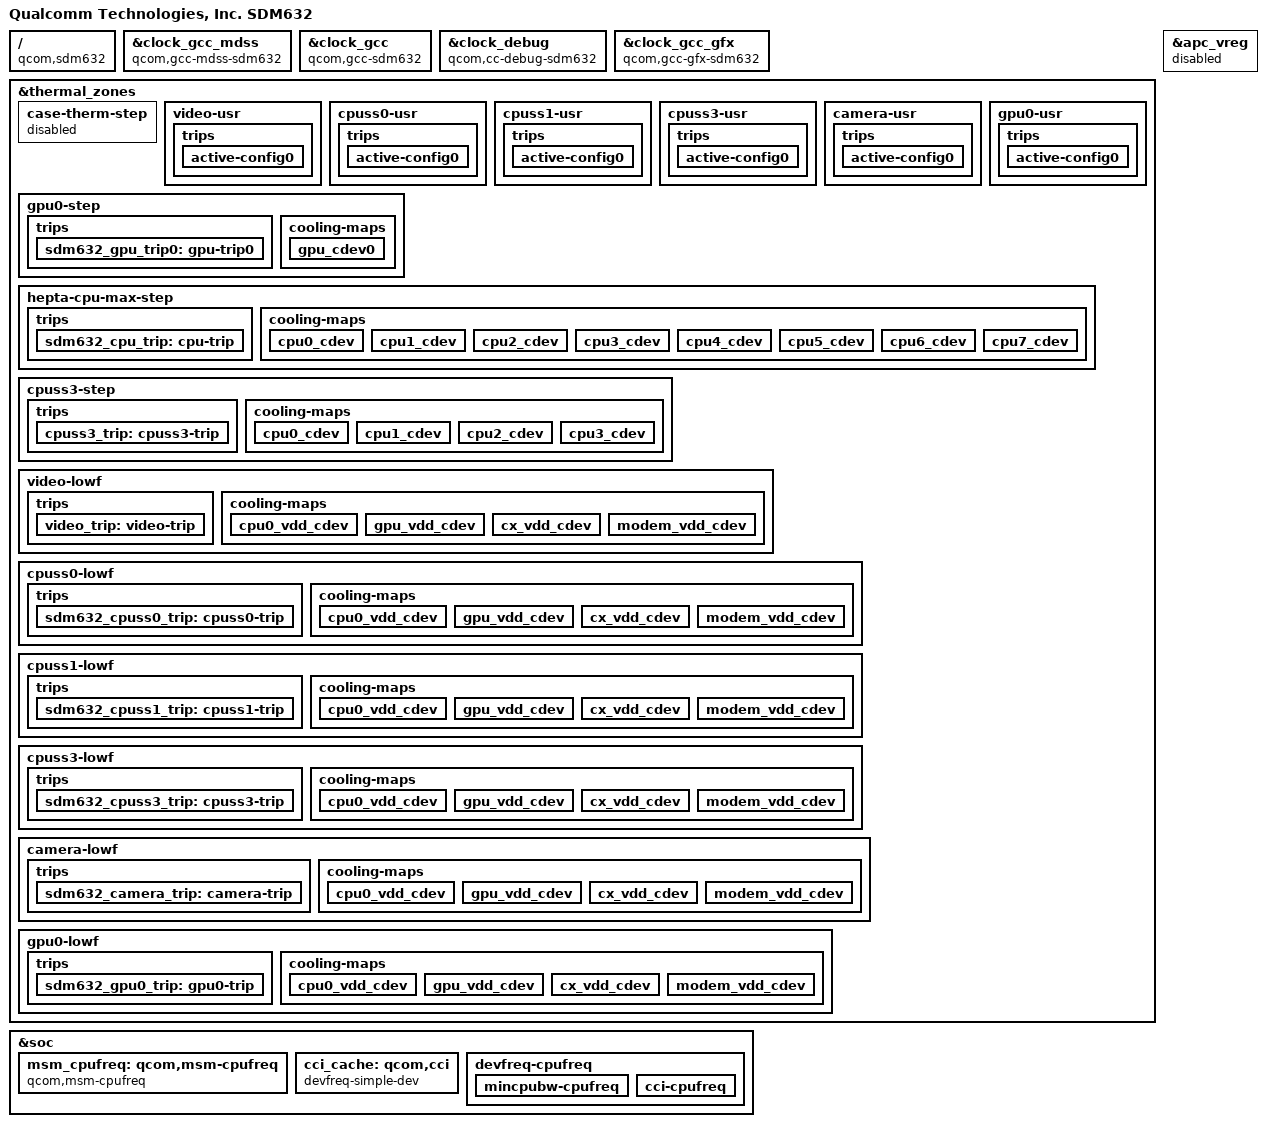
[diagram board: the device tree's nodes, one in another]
/*
 * Copyright (c) 2018, The Linux Foundation. All rights reserved.
 *
 * This program is free software; you can redistribute it and/or modify
 * it under the terms of the GNU General Public License version 2 and
 * only version 2 as published by the Free Software Foundation.
 *
 * This program is distributed in the hope that it will be useful,
 * but WITHOUT ANY WARRANTY; without even the implied warranty of
 * MERCHANTABILITY or FITNESS FOR A PARTICULAR PURPOSE.  See the
 * GNU General Public License for more details.
 */

#include "msm8953.dtsi"
#include "sdm632-cpu.dtsi"

/ {
	model = "Qualcomm Technologies, Inc. SDM632";
	compatible = "qcom,sdm632";
	qcom,msm-id = <349 0x0>;
	qcom,msm-name = "SDM632";
};

&clock_gcc_mdss {
	compatible = "qcom,gcc-mdss-sdm632";
};

&clock_gcc {
	compatible = "qcom,gcc-sdm632";
};

&clock_debug {
	compatible = "qcom,cc-debug-sdm632";
};

&clock_gcc_gfx {
	compatible = "qcom,gcc-gfx-sdm632";
};

&thermal_zones {
	/delete-node/ camera-usr;
	/delete-node/ apc1-l2-usr;
	/delete-node/ apc0-cpu0-usr;
	/delete-node/ apc0-cpu1-usr;
	/delete-node/ apc0-cpu2-usr;
	/delete-node/ apc0-cpu3-usr;
	/delete-node/ apc0-l2-usr;
	/delete-node/ gpu0-usr;
	/delete-node/ gpu1-usr;
	/delete-node/ gpu1-step;
	/delete-node/ deca-cpu-max-step;
	/delete-node/ apc0-cpu0-step;
	/delete-node/ apc0-cpu1-step;
	/delete-node/ apc0-cpu2-step;
	/delete-node/ apc0-cpu3-step;
	/delete-node/ camera-lowf;
	/delete-node/ apc1-l2-lowf;
	/delete-node/ apc0-cpu0-lowf;
	/delete-node/ apc0-cpu1-lowf;
	/delete-node/ apc0-cpu2-lowf;
	/delete-node/ apc0-cpu3-lowf;
	/delete-node/ apc0-l2-lowf;
	/delete-node/ gpu0-lowf;
	/delete-node/ gpu1-lowf;

	case-therm-step {
		status = "disabled";
	};

	video-usr {
		polling-delay-passive = <0>;
		polling-delay = <0>;
		thermal-governor = "user_space";
		thermal-sensors = <&tsens0 3>;
		trips {
			active-config0 {
				temperature = <125000>;
				hysteresis = <1000>;
				type = "passive";
			};
		};
	};

	cpuss0-usr {
		polling-delay-passive = <0>;
		polling-delay = <0>;
		thermal-sensors = <&tsens0 8>;
		thermal-governor = "user_space";
		trips {
			active-config0 {
				temperature = <125000>;
				hysteresis = <1000>;
				type = "passive";
			};
		};
	};

	cpuss1-usr {
		polling-delay-passive = <0>;
		polling-delay = <0>;
		thermal-sensors = <&tsens0 9>;
		thermal-governor = "user_space";
		trips {
			active-config0 {
				temperature = <125000>;
				hysteresis = <1000>;
				type = "passive";
			};
		};
	};

	cpuss3-usr {
		polling-delay-passive = <0>;
		polling-delay = <0>;
		thermal-sensors = <&tsens0 13>;
		thermal-governor = "user_space";
		trips {
			active-config0 {
				temperature = <125000>;
				hysteresis = <1000>;
				type = "passive";
			};
		};
	};

	camera-usr {
		polling-delay-passive = <0>;
		polling-delay = <0>;
		thermal-sensors = <&tsens0 14>;
		thermal-governor = "user_space";
		trips {
			active-config0 {
				temperature = <125000>;
				hysteresis = <1000>;
				type = "passive";
			};
		};
	};

	gpu0-usr {
		polling-delay-passive = <0>;
		polling-delay = <0>;
		thermal-sensors = <&tsens0 15>;
		thermal-governor = "user_space";
		trips {
			active-config0 {
				temperature = <125000>;
				hysteresis = <1000>;
				type = "passive";
			};
		};
	};

	gpu0-step {
		polling-delay-passive = <250>;
		polling-delay = <0>;
		thermal-sensors = <&tsens0 15>;
		thermal-governor = "step_wise";

		trips {
			sdm632_gpu_trip0: gpu-trip0 {
				temperature = <95000>;
				hysteresis = <0>;
				type = "passive";
			};
		};
		cooling-maps {
			gpu_cdev0 {
				trip = <&sdm632_gpu_trip0>;
				cooling-device =
					<&msm_gpu THERMAL_NO_LIMIT
						THERMAL_NO_LIMIT>;
			};
		};
	};

	hepta-cpu-max-step {
		polling-delay-passive = <50>;
		polling-delay = <100>;
		thermal-governor = "step_wise";

		trips {
			sdm632_cpu_trip:cpu-trip {
				temperature = <95000>;
				hysteresis = <0>;
				type = "passive";
			};
		};

		cooling-maps {
			cpu0_cdev {
				trip = <&sdm632_cpu_trip>;
				cooling-device =
					<&CPU0 THERMAL_NO_LIMIT
						(THERMAL_MAX_LIMIT-1)>;
			};
			cpu1_cdev {
				trip = <&sdm632_cpu_trip>;
				cooling-device =
					<&CPU1 THERMAL_NO_LIMIT
						(THERMAL_MAX_LIMIT-1)>;
			};
			cpu2_cdev {
				trip = <&sdm632_cpu_trip>;
				cooling-device =
					<&CPU2 THERMAL_NO_LIMIT
						(THERMAL_MAX_LIMIT-1)>;
			};
			cpu3_cdev {
				trip = <&sdm632_cpu_trip>;
				cooling-device =
					<&CPU3 THERMAL_NO_LIMIT
						(THERMAL_MAX_LIMIT-1)>;
			};
			cpu4_cdev {
				trip = <&sdm632_cpu_trip>;
				cooling-device =
					<&CPU4 THERMAL_NO_LIMIT
						(THERMAL_MAX_LIMIT-1)>;
			};
			cpu5_cdev {
				trip = <&sdm632_cpu_trip>;
				cooling-device =
					<&CPU5 THERMAL_NO_LIMIT
						(THERMAL_MAX_LIMIT-1)>;
			};
			cpu6_cdev {
				trip = <&sdm632_cpu_trip>;
				cooling-device =
					<&CPU6 THERMAL_NO_LIMIT
						(THERMAL_MAX_LIMIT-1)>;
			};
			cpu7_cdev {
				trip = <&sdm632_cpu_trip>;
				cooling-device =
					<&CPU7 THERMAL_NO_LIMIT
						(THERMAL_MAX_LIMIT-1)>;
			};
		};
	};

	cpuss3-step {
		polling-delay-passive = <0>;
		polling-delay = <0>;
		thermal-sensors = <&tsens0 13>;
		thermal-governor = "step_wise";

		trips {
			cpuss3_trip: cpuss3-trip {
				temperature = <105000>;
				hysteresis = <15000>;
				type = "passive";
			};
		};
		cooling-maps {
			cpu0_cdev {
				trip = <&cpuss3_trip>;
				cooling-device =
					<&CPU0 THERMAL_MAX_LIMIT
						THERMAL_MAX_LIMIT>;
			};
			cpu1_cdev {
				trip = <&cpuss3_trip>;
				cooling-device =
					<&CPU1 THERMAL_MAX_LIMIT
						THERMAL_MAX_LIMIT>;
			};
			cpu2_cdev {
				trip = <&cpuss3_trip>;
				cooling-device =
					<&CPU2 THERMAL_MAX_LIMIT
						THERMAL_MAX_LIMIT>;
			};
			cpu3_cdev {
				trip = <&cpuss3_trip>;
				cooling-device =
					<&CPU3 THERMAL_MAX_LIMIT
						THERMAL_MAX_LIMIT>;
			};
		};
	};

	video-lowf {
		polling-delay-passive = <0>;
		polling-delay = <0>;
		thermal-governor = "low_limits_floor";
		thermal-sensors = <&tsens0 3>;
		tracks-low;

		trips {
			video_trip: video-trip {
				temperature = <5000>;
				hysteresis = <5000>;
				type = "passive";
			};
		};
		cooling-maps {
			cpu0_vdd_cdev {
				trip = <&video_trip>;
				cooling-device = <&CPU0 (THERMAL_MAX_LIMIT - 4)
						(THERMAL_MAX_LIMIT - 4)>;
			};
			gpu_vdd_cdev {
				trip = <&video_trip>;
				cooling-device = <&msm_gpu 2 2>;
			};
			cx_vdd_cdev {
				trip = <&video_trip>;
				cooling-device = <&cx_cdev 0 0>;
			};
			modem_vdd_cdev {
				trip = <&video_trip>;
				cooling-device = <&modem_vdd 0 0>;
			};
		};
	};

	cpuss0-lowf {
		polling-delay-passive = <0>;
		polling-delay = <0>;
		thermal-governor = "low_limits_floor";
		thermal-sensors = <&tsens0 8>;
		tracks-low;

		trips {
			sdm632_cpuss0_trip: cpuss0-trip {
				temperature = <5000>;
				hysteresis = <5000>;
				type = "passive";
			};
		};
		cooling-maps {
			cpu0_vdd_cdev {
				trip = <&sdm632_cpuss0_trip>;
				cooling-device = <&CPU0 (THERMAL_MAX_LIMIT - 4)
						(THERMAL_MAX_LIMIT - 4)>;
			};
			gpu_vdd_cdev {
				trip = <&sdm632_cpuss0_trip>;
				cooling-device = <&msm_gpu 2 2>;
			};
			cx_vdd_cdev {
				trip = <&sdm632_cpuss0_trip>;
				cooling-device = <&cx_cdev 0 0>;
			};
			modem_vdd_cdev {
				trip = <&sdm632_cpuss0_trip>;
				cooling-device = <&modem_vdd 0 0>;
			};
		};
	};

	cpuss1-lowf {
		polling-delay-passive = <0>;
		polling-delay = <0>;
		thermal-governor = "low_limits_floor";
		thermal-sensors = <&tsens0 9>;
		tracks-low;

		trips {
			sdm632_cpuss1_trip: cpuss1-trip {
				temperature = <5000>;
				hysteresis = <5000>;
				type = "passive";
			};
		};
		cooling-maps {
			cpu0_vdd_cdev {
				trip = <&sdm632_cpuss1_trip>;
				cooling-device = <&CPU0 (THERMAL_MAX_LIMIT - 4)
						(THERMAL_MAX_LIMIT - 4)>;
			};
			gpu_vdd_cdev {
				trip = <&sdm632_cpuss1_trip>;
				cooling-device = <&msm_gpu 2 2>;
			};
			cx_vdd_cdev {
				trip = <&sdm632_cpuss1_trip>;
				cooling-device = <&cx_cdev 0 0>;
			};
			modem_vdd_cdev {
				trip = <&sdm632_cpuss1_trip>;
				cooling-device = <&modem_vdd 0 0>;
			};
		};
	};

	cpuss3-lowf {
		polling-delay-passive = <0>;
		polling-delay = <0>;
		thermal-governor = "low_limits_floor";
		thermal-sensors = <&tsens0 13>;
		tracks-low;

		trips {
			sdm632_cpuss3_trip: cpuss3-trip {
				temperature = <5000>;
				hysteresis = <5000>;
				type = "passive";
			};
		};
		cooling-maps {
			cpu0_vdd_cdev {
				trip = <&sdm632_cpuss3_trip>;
				cooling-device = <&CPU0 (THERMAL_MAX_LIMIT - 4)
						(THERMAL_MAX_LIMIT - 4)>;
			};
			gpu_vdd_cdev {
				trip = <&sdm632_cpuss3_trip>;
				cooling-device = <&msm_gpu 2 2>;
			};
			cx_vdd_cdev {
				trip = <&sdm632_cpuss3_trip>;
				cooling-device = <&cx_cdev 0 0>;
			};
			modem_vdd_cdev {
				trip = <&sdm632_cpuss3_trip>;
				cooling-device = <&modem_vdd 0 0>;
			};
		};
	};

	camera-lowf {
		polling-delay-passive = <0>;
		polling-delay = <0>;
		thermal-governor = "low_limits_floor";
		thermal-sensors = <&tsens0 14>;
		tracks-low;

		trips {
			sdm632_camera_trip: camera-trip {
				temperature = <5000>;
				hysteresis = <5000>;
				type = "passive";
			};
		};
		cooling-maps {
			cpu0_vdd_cdev {
				trip = <&sdm632_camera_trip>;
				cooling-device = <&CPU0 (THERMAL_MAX_LIMIT - 4)
						(THERMAL_MAX_LIMIT - 4)>;
			};
			gpu_vdd_cdev {
				trip = <&sdm632_camera_trip>;
				cooling-device = <&msm_gpu 2 2>;
			};
			cx_vdd_cdev {
				trip = <&sdm632_camera_trip>;
				cooling-device = <&cx_cdev 0 0>;
			};
			modem_vdd_cdev {
				trip = <&sdm632_camera_trip>;
				cooling-device = <&modem_vdd 0 0>;
			};
		};
	};

	gpu0-lowf {
		polling-delay-passive = <0>;
		polling-delay = <0>;
		thermal-governor = "low_limits_floor";
		thermal-sensors = <&tsens0 15>;
		tracks-low;

		trips {
			sdm632_gpu0_trip: gpu0-trip {
				temperature = <5000>;
				hysteresis = <5000>;
				type = "passive";
			};
		};
		cooling-maps {
			cpu0_vdd_cdev {
				trip = <&sdm632_gpu0_trip>;
				cooling-device = <&CPU0 (THERMAL_MAX_LIMIT - 4)
						(THERMAL_MAX_LIMIT - 4)>;
			};
			gpu_vdd_cdev {
				trip = <&sdm632_gpu0_trip>;
				cooling-device = <&msm_gpu 2 2>;
			};
			cx_vdd_cdev {
				trip = <&sdm632_gpu0_trip>;
				cooling-device = <&cx_cdev 0 0>;
			};
			modem_vdd_cdev {
				trip = <&sdm632_gpu0_trip>;
				cooling-device = <&modem_vdd 0 0>;
			};
		};
	};
};

&apc_vreg {
	status = "disabled";
};

&soc {
	/delete-node/ qcom,msm-cpufreq;
	msm_cpufreq: qcom,msm-cpufreq {
		compatible = "qcom,msm-cpufreq";
		clock-names =
			"l2_clk",
			"cpu0_clk",
			"cpu4_clk";
		clocks =
			<&clock_cpu clk_cci_clk >,
			<&clock_cpu clk_pwr_clk >,
			<&clock_cpu clk_perf_clk >;

		qcom,governor-per-policy;

		qcom,cpufreq-table-0 =
			<  614400 >,
			<  883200 >,
			< 1036800 >,
			< 1363200 >,
			< 1536000 >,
			< 1670400 >,
			< 1785600 >;

		qcom,cpufreq-table-4 =
			< 1094400 >,
			< 1401600 >,
			< 1555200 >,
			< 1785600 >,
			< 1996200 >,
			< 2082800 >;
	};

	cci_cache: qcom,cci {
		compatible = "devfreq-simple-dev";
		clock-names = "devfreq_clk";
		clocks = <&clock_cpu clk_cci_clk >;
		governor = "cpufreq";
		freq-tbl-khz =
			<  307200 >,
			<  403200 >,
			<  499200 >,
			<  691200 >,
			<  768000 >,
			<  787200 >;
	};

	/delete-node/ devfreq-cpufreq;
	devfreq-cpufreq {
		mincpubw-cpufreq {
			target-dev = <&mincpubw>;
			cpu-to-dev-map-0 =
				<  614400 1611>,
				< 1363200 3221>,
				< 1785600 5859>;
			cpu-to-dev-map-4 =
				< 1094400 1611>,
				< 1401600 3221>,
				< 1785600 5859>,
				< 2082800 7104>;
		};

		cci-cpufreq {
			target-dev = <&cci_cache>;
			cpu-to-dev-map-0 =
				<  614400 307200>,      /* SVS   */
				<  883200 403200>,
				< 1036800 499200>,
				< 1363200 691200>,      /* NOM   */
				< 1536000 768000>,      /* NOM+  */
				< 1670400 787200>;      /* TURBO */
			cpu-to-dev-map-4 =
				< 1094400 499200>,	/* SVS   */
				< 1401600 691200>,      /* NOM   */
				< 1555200 768000>,      /* NOM+  */
				< 1785600 787200>;      /* TURBO */
		};
	};
};
